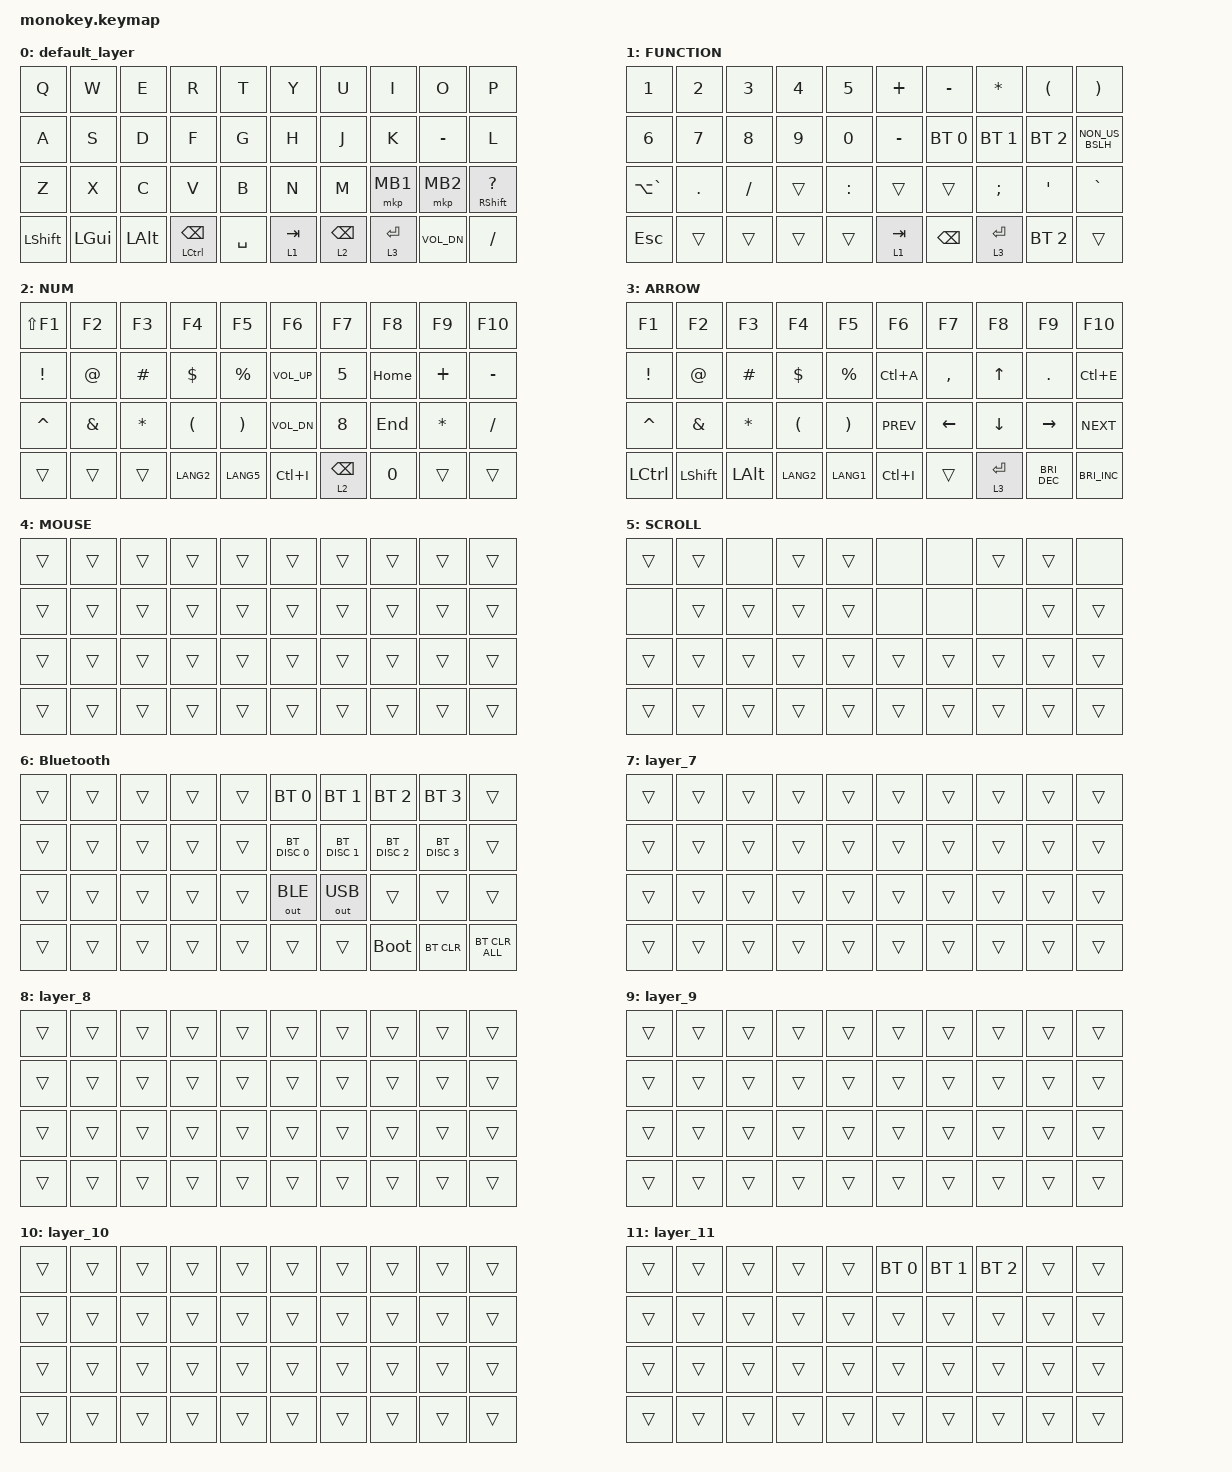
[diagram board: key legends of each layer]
#include <behaviors.dtsi>
#include <dt-bindings/zmk/bt.h>
#include <dt-bindings/zmk/keys.h>
#include <dt-bindings/zmk/outputs.h>
#include <dt-bindings/zmk/pointing.h>

&mt {
    flavor = "balanced";
    quick-tap-ms = <300>;
};

&lt { quick-tap-ms = <300>; };

/ {
    combos {
        compatible = "zmk,combos";

        scroll {
            bindings = <&mo 5>;
            key-positions = <27 28>;
        };

        esc {
            bindings = <&kp ESC>;
            key-positions = <0 1>;
        };

        gui {
            bindings = <&kp LGUI>;
            key-positions = <38 39>;
        };

        mb3 {
            bindings = <&mkp MB3>;
            key-positions = <19 18>;
        };

        caps {
            bindings = <&kp CAPSLOCK>;
            key-positions = <4 24>;
            timeout-ms = <50>;
        };
    };

    keymap {
        compatible = "zmk,keymap";

        default_layer {
            bindings = 
  &kp Q  &kp W  &kp E  &kp R  &kp T    &kp Y  &kp U  &kp I  &kp O  &kp P
  &kp A  &kp S  &kp D  &kp F  &kp G    &kp H  &kp J  &kp K  &kp MINUS  &kp L
  &kp Z  &kp X  &kp C  &kp V  &kp B    &kp N  &kp M  &mkp MB1  &mkp MB2  &mt RSHFT QMARK
  &kp LSHFT  &kp LGUI  &kp LALT  &mt LCTRL BSPC  &kp SPACE  &lt 1 TAB    &lt 2 BSPC  &lt 3 RET  &kp C_VOL_DN  &kp SLASH
            >;
        };

        FUNCTION {
            bindings = 
  &kp N1  &kp N2  &kp N3  &kp N4  &kp N5    &kp PLUS  &kp MINUS  &kp ASTRK  &kp LPAR  &kp RPAR
  &kp N6  &kp N7  &kp N8  &kp N9  &kp N0    &kp MINUS  &bt BT_SEL 0  &bt BT_SEL 1  &bt BT_SEL 2  &kp NON_US_BSLH
  &kp LA(GRAVE)  &kp DOT  &kp SLASH  &trans  &kp COLON    &trans  &trans  &kp SEMI  &kp SQT  &kp GRAVE
  &kp ESC  &trans  &trans  &trans  &trans  &lt 1 TAB    &kp BSPC  &lt 3 RET  &bt BT_SEL 2  &trans
            >;
        };

        NUM {
            bindings = 
  &kp LS(F1)  &kp F2  &kp F3  &kp F4  &kp F5    &kp F6  &kp F7  &kp F8  &kp F9  &kp F10
  &kp EXCL  &kp AT  &kp HASH  &kp DLLR  &kp PRCNT    &kp C_VOL_UP  &kp N5  &kp HOME  &kp PLUS  &kp MINUS
  &kp CARET  &kp AMPS  &kp ASTRK  &kp LPAR  &kp RPAR    &kp C_VOL_DN  &kp N8  &kp END  &kp ASTRK  &kp SLASH
  &trans  &trans  &trans  &kp LANG2  &kp LANG5  &kp LC(I)    &lt 2 BSPC  &kp N0  &trans  &trans
            >;
        };

        ARROW {
            bindings = 
  &kp F1  &kp F2  &kp F3  &kp F4  &kp F5    &kp F6  &kp F7  &kp F8  &kp F9  &kp F10
  &kp EXCL  &kp AT  &kp HASH  &kp DLLR  &kp PRCNT    &kp LC(A)  &kp COMMA  &kp UP  &kp DOT  &kp LC(E)
  &kp CARET  &kp AMPS  &kp ASTRK  &kp LPAR  &kp RPAR    &kp C_PREV  &kp LEFT  &kp DOWN  &kp RIGHT  &kp C_NEXT
  &kp LCTRL  &kp LSHFT  &kp LALT  &kp LANG2  &kp LANG1  &kp LC(I)    &trans  &lt 3 RET  &kp C_BRI_DEC  &kp C_BRI_INC
            >;
        };

        MOUSE {
            bindings = 
  &trans  &trans  &trans  &trans  &trans    &trans  &trans  &trans  &trans  &trans
  &trans  &trans  &trans  &trans  &trans    &trans  &trans  &trans  &trans  &trans
  &trans  &trans  &trans  &trans  &trans    &trans  &trans  &trans  &trans  &trans
  &trans  &trans  &trans  &trans  &trans  &trans    &trans  &trans  &trans  &trans
            >;
        };

        SCROLL {
            bindings = 
  &trans  &trans  &none  &trans  &trans    &none  &none  &trans  &trans  &none
  &none  &trans  &trans  &trans  &trans    &none  &none  &none  &trans  &trans
  &trans  &trans  &trans  &trans  &trans    &trans  &trans  &trans  &trans  &trans
  &trans  &trans  &trans  &trans  &trans  &trans    &trans  &trans  &trans  &trans
            >;
        };

        Bluetooth {
            bindings = 
  &trans  &trans  &trans  &trans  &trans    &bt BT_SEL 0  &bt BT_SEL 1  &bt BT_SEL 2  &bt BT_SEL 3  &trans
  &trans  &trans  &trans  &trans  &trans    &bt BT_DISC 0  &bt BT_DISC 1  &bt BT_DISC 2  &bt BT_DISC 3  &trans
  &trans  &trans  &trans  &trans  &trans    &out OUT_BLE  &out OUT_USB  &trans  &trans  &trans
  &trans  &trans  &trans  &trans  &trans  &trans    &trans  &bootloader  &bt BT_CLR  &bt BT_CLR_ALL
            >;
        };

        layer_7 {
            bindings = 
  &trans  &trans  &trans  &trans  &trans    &trans  &trans  &trans  &trans  &trans
  &trans  &trans  &trans  &trans  &trans    &trans  &trans  &trans  &trans  &trans
  &trans  &trans  &trans  &trans  &trans    &trans  &trans  &trans  &trans  &trans
  &trans  &trans  &trans  &trans  &trans  &trans    &trans  &trans  &trans  &trans
            >;
        };

        layer_8 {
            bindings = 
  &trans  &trans  &trans  &trans  &trans    &trans  &trans  &trans  &trans  &trans
  &trans  &trans  &trans  &trans  &trans    &trans  &trans  &trans  &trans  &trans
  &trans  &trans  &trans  &trans  &trans    &trans  &trans  &trans  &trans  &trans
  &trans  &trans  &trans  &trans  &trans  &trans    &trans  &trans  &trans  &trans
            >;
        };

        layer_9 {
            bindings = 
  &trans  &trans  &trans  &trans  &trans    &trans  &trans  &trans  &trans  &trans
  &trans  &trans  &trans  &trans  &trans    &trans  &trans  &trans  &trans  &trans
  &trans  &trans  &trans  &trans  &trans    &trans  &trans  &trans  &trans  &trans
  &trans  &trans  &trans  &trans  &trans  &trans    &trans  &trans  &trans  &trans
            >;
        };

        layer_10 {
            bindings = 
  &trans  &trans  &trans  &trans  &trans    &trans  &trans  &trans  &trans  &trans
  &trans  &trans  &trans  &trans  &trans    &trans  &trans  &trans  &trans  &trans
  &trans  &trans  &trans  &trans  &trans    &trans  &trans  &trans  &trans  &trans
  &trans  &trans  &trans  &trans  &trans  &trans    &trans  &trans  &trans  &trans
            >;
        };

        layer_11 {
            bindings = 
  &trans  &trans  &trans  &trans  &trans    &bt BT_SEL 0  &bt BT_SEL 1  &bt BT_SEL 2  &trans  &trans
  &trans  &trans  &trans  &trans  &trans    &trans  &trans  &trans  &trans  &trans
  &trans  &trans  &trans  &trans  &trans    &trans  &trans  &trans  &trans  &trans
  &trans  &trans  &trans  &trans  &trans  &trans    &trans  &trans  &trans  &trans
            >;
        };

    };
};
